# LPC11Exx register map
File version: 5
CPU: CM0 r0p0, little endian, no MPU, no FPU, 0x2 interrupt priority bits, 0x0 interrupts
Registers are 32-bit, read-write, reset 0x0 unless marked. A register's access mark holds for its fields unless they carry their own. Offsets are from the block's base; [hi:lo] are bit positions; {n}, {i} and the like mark numbered series.

## PMU — Power Management Unit (PMU)
Base 0x40038000
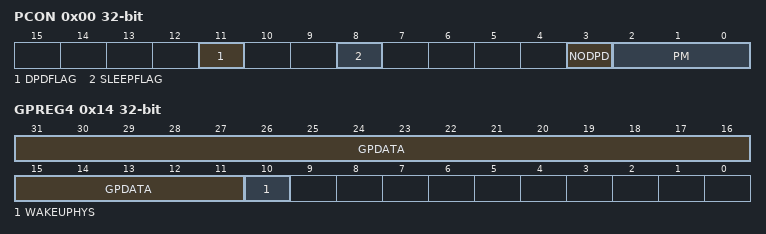
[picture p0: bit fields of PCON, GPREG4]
0x00 PCON — Power control register
  [11] DPDFLAG — Deep power-down flag
    0=DPNOTENTERED (Read: Deep power-down mode not entered. Write: No effect.); 1=DPENTERED (Read: Deep power-down mode entered. Write: Clear the Deep power-down flag.)
  [8] SLEEPFLAG — Sleep mode flag
    0=NOPOWERDOWN (Read: No power-down mode entered. LPC11U1x is in Active mode. Write: No effect.); 1=POWERDOWN (Read: Sleep/Deep-sleep or Deep power-down mode entered. Write: Writing a 1 clears the SLEEPFLAG bit to 0.)
  [3] NODPD — A 1 in this bit prevents entry to Deep power-down mode when 0x3 is written to the PM field above, the SLEEPDEEP bit is set, and a WFI is executed. Execution continues after the WFI if this bit is 1. This bit is cleared only by power-on reset, so writing a one to this bit locks the part in a mode in which Deep power-down mode is blocked.
  [2:0] PM — Power mode
    0=DEFAULT (Default. The part is in active or sleep mode.); 1=DEEPSLEEP (ARM WFI will enter Deep-sleep mode.); 2=POWERDOWN (ARM WFI will enter Power-down mode.); 3=DEEPPOWERDOWN (ARM WFI will enter Deep-power down mode (ARM Cortex-M0 core powered-down).)
{0x4+4i} GPREG{i} (i=0..3) — General purpose register 0
  [31:0] GPDATA — Data retained during Deep power-down mode.
0x14 GPREG4 — General purpose register 4
  [31:11] GPDATA — Data retained during Deep power-down mode.
  [10] WAKEUPHYS — WAKEUP pin hysteresis enable
    0=DISABLED (Hysteresis for WAKEUP pin disabled.); 1=ENABLED (Hysteresis for WAKEUP pin enabled.)

## FLASHCTRL — Flash programming firmware Modification
Base 0x4003C000
0x10 FLASHCFG reset not defined — Flash memory access time configuration register
  [1:0] FLASHTIM — Flash memory access time. FLASHTIM +1 is equal to the number of system clocks used for flash access.
    0=1_SYSTEM_CLOCK_FLASH (1 system clock flash access time (for system clock frequencies of up to 20 MHz).); 1=2_SYSTEM_CLOCKS_FLAS (2 system clocks flash access time (for system clock frequencies of up to 40 MHz).); 2=3_SYSTEM_CLOCKS_FLAS (3 system clocks flash access time (for system clock frequencies of up to 50 MHz).)
0x20 FMSSTART — Signature start address register
  [16:0] START — Signature generation start address (corresponds to AHB byte address bits[20:4]).
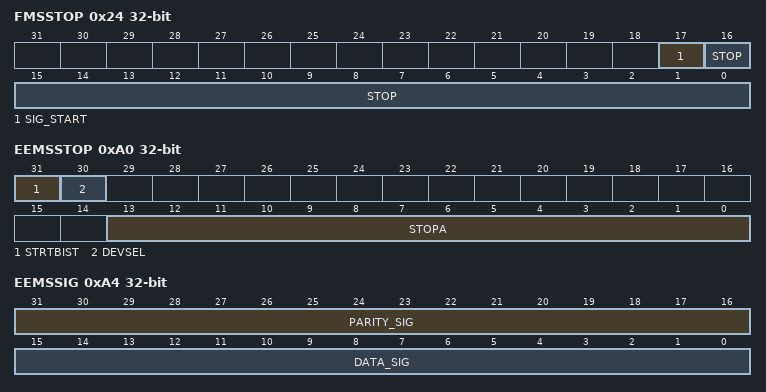
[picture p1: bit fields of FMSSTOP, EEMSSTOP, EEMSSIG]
0x24 FMSSTOP — Signature stop-address register
  [17] SIG_START — Start control bit for signature generation.
    0=SIGNATURE_GENERATION (Signature generation is stopped); 1=INITIATE_SIGNATURE_G (Initiate signature generation)
  [16:0] STOP — BIST stop address divided by 16 (corresponds to AHB byte address [20:4]).
{0x2C+4i} FMSW{i} ro reset not defined (i=0..3) — Word {i} [{32i+31}:{32i}]
  [31:0] SW{i}_{32i+31}_{32i} — Word {i} of 128-bit signature (bits {32i+31} to {32i}).
0x9C EEMSSTART — EEPROM BIST start address register
  [13:0] STARTA — BIST start address: Bit 0 is fixed zero since only even addresses are allowed.
0xA0 EEMSSTOP — EEPROM BIST stop address register
  [31] STRTBIST — BIST start bit Setting this bit will start the BIST. This bit is self-clearing.
  [30] DEVSEL — BIST device select bit 0: the BIST signature is generated over the total memory space. Singe pages are interleaved over the EEPROM devices when multiple devices are used, the signature is generated over memory of multiple devices. 1: the BIST signature is generated only over a memory range located on a single EEPROM device. Therefore the internal address generation is done such that the address' CS bits are kept stable to select only the same device. The address' MSB and LSB bits are used to step through the memory range specified by the start and stop address fields. Note: if this bit is set the start and stop address fields must be programmed such that they both address the same EEPROM device. Therefore the address' CS bits in both the start and stop address must be the same.
  [13:0] STOPA — BIST stop address: Bit 0 is fixed zero since only even addresses are allowed.
0xA4 EEMSSIG ro — EEPROM 24-bit BIST signature register
  [31:16] PARITY_SIG — BIST 16-bit signature calculated from only the parity bits of the data bytes
  [15:0] DATA_SIG — BIST 16-bit signature calculated from only the data bytes
0xFE0 FMSTAT ro — Signature generation status register
  [2] SIG_DONE — When 1, a previously started signature generation has completed. See FMSTATCLR register description for clearing this flag.
0xFE8 FMSTATCLR wo reset not defined — Signature generation status clear register
  [2] SIG_DONE_CLR — Writing a 1 to this bits clears the signature generation completion flag (SIG_DONE) in the FMSTAT register.
